# R7FA6M5BH register map
Vendor: Renesas Electronics Corporation; Series: RA6; File version: 1.20.01
CPU: CM33 r0p4, little endian, MPU, FPU, VTOR, 4 interrupt priority bits, 96 interrupts
Registers are 32-bit, read-write, reset 0x0 unless marked. A register's access mark holds for its fields unless they carry their own. Offsets are from the block's base; [hi:lo] are bit positions.

## AGT0 — Low Power Asynchronous General Purpose Timer 0
Base 0x400E8000
Same registers: AGT1 0x400E8100, AGT2 0x400E8200, AGT3 0x400E8300, AGT4 0x400E8400, AGT5 0x400E8500
0x00 AGT 16-bit reset 0xFFFF — AGT Counter Register
0x02 AGTCMA 16-bit reset 0xFFFF — AGT Compare Match A Register
0x04 AGTCMB 16-bit reset 0xFFFF — AGT Compare Match B Register
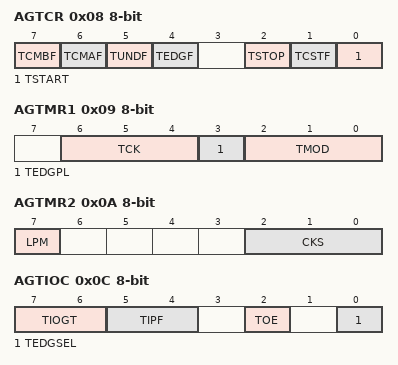
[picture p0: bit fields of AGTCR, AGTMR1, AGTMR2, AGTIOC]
0x08 AGTCR 8-bit — AGT Control Register
  [7] TCMBF — Compare Match B Flag
    0=No match; 1=Match
  [6] TCMAF — Compare Match A Flag
    0=No match; 1=Match
  [5] TUNDF — Underflow Flag
    0=No underflow; 1=Underflow
  [4] TEDGF — Active Edge Judgment Flag
    0=No active edge received; 1=Active edge received
  [2] TSTOP wo — AGT Count Forced Stop
    0=Writing is invalid; 1=The count is forcibly stopped
  [1] TCSTF ro — AGT Count Status Flag
    0=Count stopped; 1=Count in progress
  [0] TSTART — AGT Count Start
    0=Count stops; 1=Count starts
0x09 AGTMR1 8-bit — AGT Mode Register 1
  [6:4] TCK — Count Source
    0=PCLKB; 1=PCLKB/8; 3=PCLKB/2; 4=Divided clock AGTLCLK specified by CKS[2:0] bits in the AGTMR2 register; 5=Underflow event signal from AGTn (n = 0, 2, 4); 6=Divided clock AGTSCLK specified by CKS[2:0] bits in the AGTMR2 register; other=Others (Setting prohibited)
  [3] TEDGPL — Edge Polarity
    0=Single-edge; 1=Both-edge
  [2:0] TMOD — Operating Mode
    0=Timer mode; 1=Pulse output mode; 2=Event counter mode; 3=Pulse width measurement mode; 4=Pulse period measurement mode; other=Others (Setting prohibited)
0x0A AGTMR2 8-bit — AGT Mode Register 2
  [7] LPM — Low Power Mode
    0=Normal mode; 1=Low power mode
  [2:0] CKS — AGTLCLK or AGTSCLK Count Source Clock Frequency Division Ratio
    0=1/1; 1=1/2; 2=1/4; 3=1/8; 4=1/16; 5=1/32; 6=1/64; 7=1/128
0x0C AGTIOC 8-bit — AGT I/O Control Register
  [7:6] TIOGT — Count Control
    0=Event is always counted; 1=Event is counted during polarity period specified for AGTEEn pin; other=Others (Setting prohibited)
  [5:4] TIPF — Input Filter
    0=No filter; 1=Filter sampled at PCLKB; 2=Filter sampled at PCLKB/8; 3=Filter sampled at PCLKB/32
  [2] TOE — AGTOn pin Output Enable
    0=AGTOn pin output disabled; 1=AGTOn pin output enabled
  [0] TEDGSEL — I/O Polarity Switch
0x0D AGTISR 8-bit — AGT Event Pin Select Register
  [2] EEPS — AGTEEn Polarity Selection
    0=An event is counted during the low-level period; 1=An event is counted during the high-level period
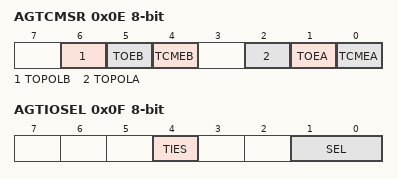
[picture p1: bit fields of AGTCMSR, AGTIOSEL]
0x0E AGTCMSR 8-bit — AGT Compare Match Function Select Register
  [6] TOPOLB — AGTOBn Pin Polarity Select
    0=AGTOBn pin output is started on low. i.e. normal output; 1=AGTOBn pin output is started on high. i.e. inverted output
  [5] TOEB — AGTOBn Pin Output Enable
    0=AGTOBn pin output disabled; 1=AGTOBn pin output enabled
  [4] TCMEB — AGT Compare Match B Register Enable
    0=Compare match B register disabled; 1=Compare match B register enabled
  [2] TOPOLA — AGTOAn Pin Polarity Select
    0=AGTOAn pin output is started on low. i.e. normal output; 1=AGTOAn pin output is started on high. i.e. inverted output
  [1] TOEA — AGTOAn Pin Output Enable
    0=AGTOAn pin output disabled; 1=AGTOAn pin output enabled
  [0] TCMEA — AGT Compare Match A Register Enable
    0=AGT Compare match A register disabled; 1=AGT Compare match A register enabled
0x0F AGTIOSEL 8-bit — AGT Pin Select Register
  [4] TIES — AGTIOn Pin Input Enable
    0=External event input is disabled during Software Standby mode; 1=External event input is enabled during Software Standby mode
  [1:0] SEL — AGTIOn Pin Select
    0=Select Pm/AGTIO as AGTIO. Pm/AGTIO can not be used as AGTIO input pin in Deep Software Standby mode. (m = 100, 301, 407, and 705 (AGT0), m = 204 and 400 (AGT1), m = 103 (AGT2), m = 600(AGT3).); 1=Select P404/AGTIO as AGTIO P404/AGTIO can be used as AGTIO input pin in Deep Software Standby mode. P404/AGTIOn is input only. It cannot be used for output.; 2=Select P402/AGTIO as AGTIO P402/AGTIO can be used as AGTIO input pin in Deep Software Standby mode. P402/AGTIOn is input only. It cannot be used for output.; 3=Select P403/AGTIO as AGTIO. P403/AGTIO can be used as AGTIO input pin in Deep Software Standby mode. P403/AGTIOn is input only. It cannot be used for output.
